VERSION ""

NS_ :

BS_:

BU_: FC PI

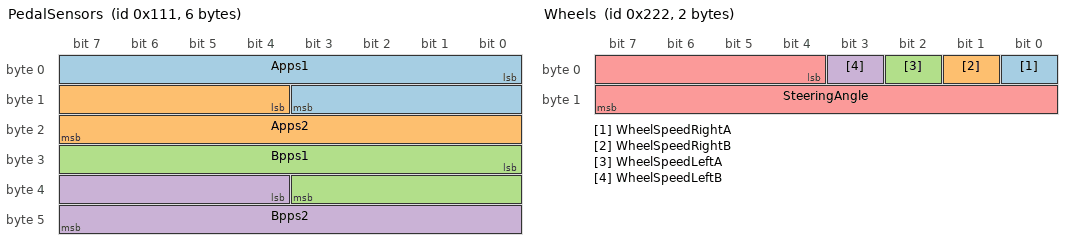
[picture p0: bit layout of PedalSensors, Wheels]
BO_ 273 PedalSensors: 6 FC
    SG_ Apps1 : 0|12@1+ (1.0000001,0) [0|3.3] "V" PI
    SG_ Apps2 : 12|12@1+ (1.0000001,0) [0|3.3] "V" PI
    SG_ Bpps1 : 24|12@1+ (1.0000001,0) [0|3.3] "V" PI
    SG_ Bpps2 : 36|12@1+ (1.0000001,0) [0|3.3] "V" PI

BO_ 546 Wheels: 2 FC
    SG_ WheelSpeedRightA : 0|1@1+ (1,0) [0|1] "" PI
    SG_ WheelSpeedRightB : 1|1@1+ (1,0) [0|1] "" PI
    SG_ WheelSpeedLeftA : 2|1@1+ (1,0) [0|1] "" PI
    SG_ WheelSpeedLeftB : 3|1@1+ (1,0) [0|1] "" PI
    SG_ SteeringAngle : 4|12@1+ (1.0000001,0) [0|3.3] "V" PI

BO_ 819 VehicleInfo: 4 FC
    SG_ HvilFeedback : 0|12@1+ (1.0000001,0) [0|3.3] "V" PI
    SG_ StartButton : 24|1@1+ (1,0) [0|0] "" PI

BO_ 1092 Suspension: 3 FC
    SG_ SuspensionTravel1 : 0|12@1+ (1.0000001,0) [0|3.3] "V" PI
    SG_ SuspensionTravel2 : 12|12@1+ (1.0000001,0) [0|3.3] "V" PI

BO_ 123 RequiredRxMessage: 1 PI
    SG_ DoNotUseMe : 0|1@1+ (1,0) [0|1] "" FC
    SG_ ThisWillBeRemovedSoon : 1|1@1+ (1,0) [0|1] "" FC
